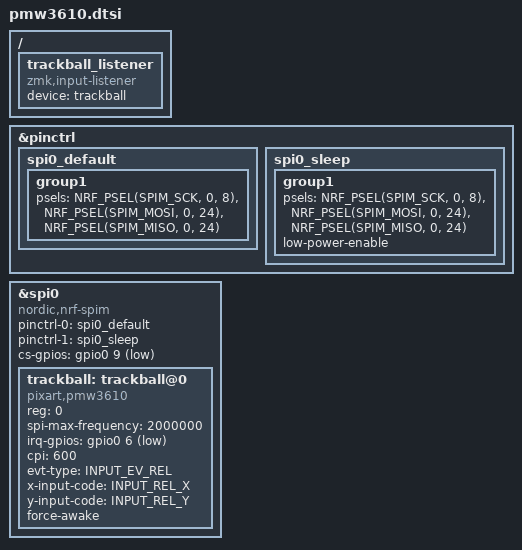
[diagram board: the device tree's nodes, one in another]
#define INPUT_EV_KEY 0x01
#define INPUT_EV_REL 0x02
#define INPUT_EV_ABS 0x03
#define INPUT_EV_MSC 0x04
#define INPUT_EV_VENDOR_START 0xf0
#define INPUT_EV_VENDOR_STOP 0xff

#define INPUT_REL_X 0x00
#define INPUT_REL_Y 0x01
#define INPUT_REL_WHEEL 0x08
#define INPUT_REL_HWHEEL 0x06
#define INPUT_REL_MISC 0x09

&pinctrl {
    spi0_default: spi0_default {
        group1 {
            psels = <NRF_PSEL(SPIM_SCK,  0, 8)>,  // SCLK → P0.08 (SCL pad, pin 6)
                    <NRF_PSEL(SPIM_MOSI, 0, 24)>, // SDIO → P0.24 (pin 8 hole)
                    <NRF_PSEL(SPIM_MISO, 0, 24)>;
        };
    };

    spi0_sleep: spi0_sleep {
        group1 {
            psels = <NRF_PSEL(SPIM_SCK,  0, 8)>,
                    <NRF_PSEL(SPIM_MOSI, 0, 24)>,
                    <NRF_PSEL(SPIM_MISO, 0, 24)>;
            low-power-enable;
        };
    };
};

#include <zephyr/dt-bindings/input/input-event-codes.h>

&spi0 {
    status = "okay";
    compatible = "nordic,nrf-spim";
    pinctrl-0 = <&spi0_default>;
    pinctrl-1 = <&spi0_sleep>;
    pinctrl-names = "default", "sleep";
    cs-gpios = <&gpio0 9 GPIO_ACTIVE_LOW>; // NCS → P0.09 (pin 13 hole)

    trackball: trackball@0 {
        status = "okay";
        compatible = "pixart,pmw3610";
        reg = <0>;
        spi-max-frequency = <2000000>;
        irq-gpios = <&gpio0 6 (GPIO_ACTIVE_LOW | GPIO_PULL_UP)>; // MOT → P0.06 (SDA pad, pin 5)
        cpi = <600>;
        evt-type = <INPUT_EV_REL>;
        x-input-code = <INPUT_REL_X>;
        y-input-code = <INPUT_REL_Y>;

        force-awake;
    };
};

/ {
    trackball_listener {
        compatible = "zmk,input-listener";
        device = <&trackball>;
    };
};
